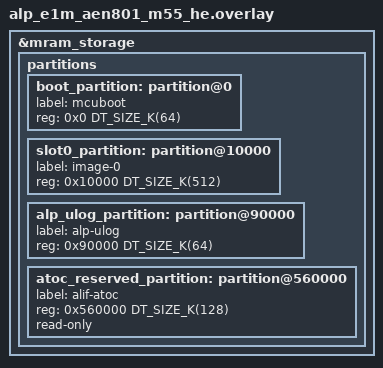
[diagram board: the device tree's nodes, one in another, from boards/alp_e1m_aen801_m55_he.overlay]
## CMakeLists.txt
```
# SPDX-License-Identifier: Apache-2.0
cmake_minimum_required(VERSION 3.20.0)

set(ALP_AEN_UPDATE_LOG_FIREWALL_PROVEN OFF CACHE BOOL
    "Enable only after the AEN MRAM log partition is firewalled and silicon-proven")
set(ALP_AEN_UPDATE_LOG_FIREWALL_PROBE OFF CACHE BOOL
    "Build the HE direct-write MRAM firewall probe instead of the normal HE demo")

if(ALP_AEN_UPDATE_LOG_FIREWALL_PROVEN AND ALP_AEN_UPDATE_LOG_FIREWALL_PROBE)
  message(FATAL_ERROR "Use either ALP_AEN_UPDATE_LOG_FIREWALL_PROVEN or ALP_AEN_UPDATE_LOG_FIREWALL_PROBE, not both")
endif()

# The AEN bench images are loaded to each M55's ITCM by a dual-entry ATOC, while
# the update log itself persists in a dedicated MRAM NVS partition. HE is the
# app/client image; HP is the trusted owner image. Keep this board-only so
# native_sim stays the portable, no-hardware test path.
if(BOARD MATCHES "^alp_e1m_aen801_m55_he")
  set(DTC_OVERLAY_FILE "${CMAKE_CURRENT_SOURCE_DIR}/boards/alp_e1m_aen801_m55_he_ae822fa0e5597ls0_rtss_he.overlay")
  list(APPEND EXTRA_CONF_FILE "${CMAKE_CURRENT_SOURCE_DIR}/boards/alp_e1m_aen801_m55_he_ae822fa0e5597ls0_rtss_he.conf")
  if(ALP_AEN_UPDATE_LOG_FIREWALL_PROVEN)
    message(STATUS "AEN update-log firewall-proof profile enabled")
    list(APPEND EXTRA_CONF_FILE "${CMAKE_CURRENT_SOURCE_DIR}/boards/alp_e1m_aen801_m55_he_firewall_proven.conf")
  endif()
  if(ALP_AEN_UPDATE_LOG_FIREWALL_PROBE)
    message(STATUS "AEN update-log HE direct-write firewall probe enabled")
    list(APPEND EXTRA_CONF_FILE "${CMAKE_CURRENT_SOURCE_DIR}/boards/alp_e1m_aen801_m55_he_firewall_probe.conf")
  endif()
elseif(BOARD MATCHES "^alp_e1m_aen801_m55_hp")
  set(DTC_OVERLAY_FILE "${CMAKE_CURRENT_SOURCE_DIR}/boards/alp_e1m_aen801_m55_hp_ae822fa0e5597ls0_rtss_hp.overlay")
  list(APPEND EXTRA_CONF_FILE "${CMAKE_CURRENT_SOURCE_DIR}/boards/alp_e1m_aen801_m55_hp_ae822fa0e5597ls0_rtss_hp.conf")
endif()

find_package(Zephyr REQUIRED HINTS $ENV{ZEPHYR_BASE})
project(firmware_update_log)

# flash-update-log-dual.sh greps the build's .config for FIREWALL_PROVEN, and the
# HE client only reports HW_ENFORCED with it. Fail the configure step if the
# profile was requested but the Kconfig did not derive it.
if(ALP_AEN_UPDATE_LOG_FIREWALL_PROVEN AND NOT CONFIG_ALP_SDK_UPDATE_LOG_AEN_M55_FIREWALL_PROVEN)
  message(FATAL_ERROR "ALP_AEN_UPDATE_LOG_FIREWALL_PROVEN=ON but the app-immutable profile did not derive CONFIG_ALP_SDK_UPDATE_LOG_AEN_M55_FIREWALL_PROVEN")
endif()
target_sources(app PRIVATE src/main.c)
```

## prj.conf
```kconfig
CONFIG_PRINTK=y
CONFIG_LOG=y
CONFIG_ALP_SDK=y
CONFIG_ALP_SDK_UPDATE_LOG=y

# The update-log engine hashes records on the caller's stack. Keep enough
# main-thread stack for Cortex-M builds with hardware stack protection enabled.
CONFIG_MAIN_STACK_SIZE=4096
```

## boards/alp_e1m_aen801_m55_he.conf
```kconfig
#
# E1M-AEN801 / Alif Ensemble E8: load the HE client to ITCM. HE never opens a
# local persistent update-log store: it is a CLIENT of the HP owner and only
# ever reaches the log by proxying append/verify/count/get over MHU.
#
# alp_ulog_partition is mapped in the shared *_log_mram.dtsi purely so the HP
# owner build (which includes the same dtsi) can carve it out, and so the
# firewall-probe profile can attempt a direct raw flash_write() against it as
# a negative proof. HE's own update-log backend selection must NEVER mount a
# local NVS store on that partition -- it is the HP owner's MRAM region, and
# the update-log engine's lock is per-image, so two NVS instances over one
# region would race with no cross-image serialization. Do NOT set
# CONFIG_ALP_SDK_UPDATE_LOG_PERSIST / CONFIG_NVS here: the software tier's
# ready() probe additionally refuses to engage at all on this CLIENT role
# (src/backends/update_log/sw_tier.c) so this stays fail-closed even if PERSIST
# were mistakenly re-enabled.
#
# This is a client role, not app-immutability by itself. The active assurance
# still comes from alp_update_log_assurance(); it becomes HW_ENFORCED only
# when the real secure owner/firewall-backed backend answers ready().
#
# Keep the AEN bench image fail-closed for the customer policy: if the secure
# owner is not present, the example reports that and exits instead of using a
# local software MRAM/NVS tier as a substitute.
CONFIG_ALP_SOC_ALIF_ENSEMBLE_E8=y
CONFIG_ALP_SDK_UPDATE_LOG_AEN_M55_CLIENT=y
CONFIG_ALP_SDK_UPDATE_LOG_REQUIRE_HW_ENFORCED=y

# Do not set CONFIG_ALP_SDK_UPDATE_LOG_AEN_M55_FIREWALL_PROVEN here. That bit is
# only valid in a provisioned profile after a real HE write-to-log-region probe
# has faulted/rejected on silicon. Without it the HE image remains fail-closed.

# Shared HE<->HP request mailbox lives in global SRAM0. Keep D-cache off until
# the service grows explicit clean/invalidate around that mailbox.
CONFIG_DCACHE=n

# The Alif MRAM flash driver, kept enabled only so the firewall-probe profile
# (EXTRA_CONF_FILE-layered on top of this file) can flash_write()/flash_read()
# alp_ulog_partition directly as its negative proof. HE's own update-log path
# does not use it -- see the comment block above.
CONFIG_FLASH=y
CONFIG_FLASH_MAP=y
CONFIG_FLASH_PAGE_LAYOUT=y
```

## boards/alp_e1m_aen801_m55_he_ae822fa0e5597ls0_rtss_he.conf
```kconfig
#
# E1M-AEN801 / Alif Ensemble E8: load the HE client to ITCM. HE never opens a
# local persistent update-log store: it is a CLIENT of the HP owner and only
# ever reaches the log by proxying append/verify/count/get over MHU.
#
# alp_ulog_partition is mapped in the shared *_log_mram.dtsi purely so the HP
# owner build (which includes the same dtsi) can carve it out, and so the
# firewall-probe profile can attempt a direct raw flash_write() against it as
# a negative proof. HE's own update-log backend selection must NEVER mount a
# local NVS store on that partition -- it is the HP owner's MRAM region, and
# the update-log engine's lock is per-image, so two NVS instances over one
# region would race with no cross-image serialization. Do NOT set
# CONFIG_ALP_SDK_UPDATE_LOG_PERSIST / CONFIG_NVS here: the software tier's
# ready() probe additionally refuses to engage at all on this CLIENT role
# (src/backends/update_log/sw_tier.c) so this stays fail-closed even if PERSIST
# were mistakenly re-enabled.
#
# This is a client role, not app-immutability by itself. The active assurance
# still comes from alp_update_log_assurance(); it becomes HW_ENFORCED only
# when the real secure owner/firewall-backed backend answers ready().
#
# Keep the AEN bench image fail-closed for the customer policy: if the secure
# owner is not present, the example reports that and exits instead of using a
# local software MRAM/NVS tier as a substitute.
CONFIG_ALP_SOC_ALIF_ENSEMBLE_E8=y
CONFIG_ALP_SDK_UPDATE_LOG_AEN_M55_CLIENT=y
CONFIG_ALP_SDK_UPDATE_LOG_REQUIRE_HW_ENFORCED=y

# Do not select CONFIG_ALP_SDK_UPDATE_LOG_AEN_M55_APP_IMMUTABLE_PROFILE here.
# It is only valid in a provisioned profile (boards/*_firewall_proven.conf,
# -DALP_AEN_UPDATE_LOG_FIREWALL_PROVEN=ON) after a real HE write-to-log-region
# probe has faulted/rejected on silicon. Without it the HE image remains
# fail-closed.

# Shared HE<->HP request mailbox lives in global SRAM0. Keep D-cache off until
# the service grows explicit clean/invalidate around that mailbox.
CONFIG_DCACHE=n

# The Alif MRAM flash driver, kept enabled only so the firewall-probe profile
# (EXTRA_CONF_FILE-layered on top of this file) can flash_write()/flash_read()
# alp_ulog_partition directly as its negative proof. HE's own update-log path
# does not use it -- see the comment block above.
CONFIG_FLASH=y
CONFIG_FLASH_MAP=y
CONFIG_FLASH_PAGE_LAYOUT=y
```

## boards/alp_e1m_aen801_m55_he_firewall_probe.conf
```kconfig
#
# E1M-AEN801 / Alif Ensemble E8: HE direct-write firewall probe.
#
# This diagnostic profile intentionally tries to write the first 16 bytes of
# alp_ulog_partition from the HE application core. It is a negative proof: the
# hardware-enforced update-log profile is valid only if this write is rejected,
# blocked from readback, or faults while the MRAM log partition remains
# unchanged.
#
# Do not combine this with CONFIG_ALP_SDK_UPDATE_LOG_AEN_M55_APP_IMMUTABLE_PROFILE.
# The normal demo uses the proven profile after this probe has passed.
#
CONFIG_ALP_SDK_UPDATE_LOG_AEN_M55_FIREWALL_PROBE=y
CONFIG_FAULT_DUMP=2
```

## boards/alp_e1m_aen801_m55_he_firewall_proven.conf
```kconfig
#
# E1M-AEN801 / Alif Ensemble E8: provisioned app-immutable update-log profile.
#
# Select this profile (-DALP_AEN_UPDATE_LOG_FIREWALL_PROVEN=ON) only for a
# board whose provisioning has already locked alp_ulog_partition so the HE
# application core cannot write or erase it, and where that direct-write
# rejection has been proven on silicon with the firewall-probe profile.
#
# This does not program the firewall. It is the one flag that lets the HE
# client report HW_ENFORCED after the HP owner also answers the MHU ready
# request. The Kconfig derives CONFIG_ALP_SDK_UPDATE_LOG_AEN_M55_FIREWALL_PROVEN
# and selects CONFIG_ALP_SDK_UPDATE_LOG_REQUIRE_HW_ENFORCED from it, so do not
# set either of those by hand.
#
CONFIG_ALP_SDK_UPDATE_LOG_AEN_M55_APP_IMMUTABLE_PROFILE=y
```

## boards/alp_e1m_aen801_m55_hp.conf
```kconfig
#
# E1M-AEN801 / Alif Ensemble E8: trusted-owner side of the hardware-enforced
# update-log demo. HP owns the MRAM log partition and services HE requests over
# the RTSS MHU mailbox.
#
CONFIG_ALP_SOC_ALIF_ENSEMBLE_E8=y
CONFIG_ALP_SDK_UPDATE_LOG_AEN_M55_OWNER=y

# HP is the trusted writer, so it opens the local MRAM/NVS log directly. Do not
# require HW_ENFORCED on this side; the HE client is the side that reports the
# security property after the firewall proof and owner-ready checks pass.
CONFIG_ALP_SDK_UPDATE_LOG_REQUIRE_HW_ENFORCED=n

# HP releases HE over the Alif SE service after the dual-image package has
# loaded the HE image but before the owner starts serving requests.
CONFIG_ARM_MHUV2=y
CONFIG_HAS_ALIF_SE_SERVICES=y
CONFIG_ALP_SDK_SECURITY_SE_CRYPTOCELL=n
CONFIG_ALP_SDK_SOC_INFO_ALIF_SE=n
CONFIG_ALP_SDK_POWER_PROFILE_ALIF_SE=n

# Link at the board's zephyr,code-partition (&slot0_partition), so Flow-D
# flashing writes an image whose reset vector is in MRAM slot0 (0x8001xxxx).
CONFIG_USE_DT_CODE_PARTITION=y

# Shared HE<->HP request mailbox lives in global SRAM0. Keep D-cache off until
# the service grows explicit clean/invalidate around that mailbox.
CONFIG_DCACHE=n

# Zephyr NVS over the Alif MRAM flash driver backs alp_ulog_partition.
CONFIG_FLASH=y
CONFIG_FLASH_MAP=y
CONFIG_FLASH_PAGE_LAYOUT=y
CONFIG_NVS=y
CONFIG_ALP_SDK_UPDATE_LOG_PERSIST=y
```

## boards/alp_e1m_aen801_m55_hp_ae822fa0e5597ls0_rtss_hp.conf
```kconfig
#
# E1M-AEN801 / Alif Ensemble E8: trusted-owner side of the hardware-enforced
# update-log demo. HP owns the MRAM log partition and services HE requests over
# the RTSS MHU mailbox.
#
CONFIG_ALP_SOC_ALIF_ENSEMBLE_E8=y
CONFIG_ALP_SDK_UPDATE_LOG_AEN_M55_OWNER=y

# HP is the trusted writer, so it opens the local MRAM/NVS log directly. Do not
# require HW_ENFORCED on this side; the HE client is the side that reports the
# security property after the firewall proof and owner-ready checks pass.
CONFIG_ALP_SDK_UPDATE_LOG_REQUIRE_HW_ENFORCED=n

# HP releases HE over the Alif SE service after the dual-image package has
# loaded the HE image but before the owner starts serving requests.
CONFIG_ARM_MHUV2=y
CONFIG_HAS_ALIF_SE_SERVICES=y
CONFIG_ALP_SDK_SECURITY_SE_CRYPTOCELL=n
CONFIG_ALP_SDK_SOC_INFO_ALIF_SE=n
CONFIG_ALP_SDK_POWER_PROFILE_ALIF_SE=n

# Shared HE<->HP request mailbox lives in global SRAM0. Keep D-cache off until
# the service grows explicit clean/invalidate around that mailbox.
CONFIG_DCACHE=n

# Zephyr NVS over the Alif MRAM flash driver backs alp_ulog_partition.
CONFIG_FLASH=y
CONFIG_FLASH_MAP=y
CONFIG_FLASH_PAGE_LAYOUT=y
CONFIG_NVS=y
CONFIG_ALP_SDK_UPDATE_LOG_PERSIST=y
```

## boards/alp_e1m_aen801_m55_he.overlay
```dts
/*
 * Copyright 2026 Alp Lab AB
 * SPDX-License-Identifier: Apache-2.0
 *
 * E1M-AEN801 / Alif Ensemble E8 MRAM layout for firmware-update-log.
 *
 * The board's production MRAM map uses the top 128 KiB as generic storage.
 * The Alif ATOC package also lives at the top of MRAM in the Flow-D boot path,
 * so this example uses a smaller demo map:
 *
 *   0x000000..0x00ffff  boot placeholder
 *   0x010000..0x08ffff  slot0 image, booted by the SE from MRAM
 *   0x090000..0x09ffff  alp_ulog_partition, Zephyr NVS update-log store
 *   0x560000..0x57ffff  reserved for the Alif ATOC package
 *
 * The update-log partition is deliberately away from the ATOC area. In the
 * hardware-enforced flow, HP owns this partition and HE must be blocked from
 * writing it by the SE/device firewall. Without that firewall policy, MRAM/NVS
 * is only persistence, not app-immutability.
 */

/delete-node/ &boot_partition;
/delete-node/ &slot0_partition;
/delete-node/ &slot1_partition;
/delete-node/ &scratch_partition;
/delete-node/ &storage_partition;

&mram_storage {
	partitions {
		boot_partition: partition@0 {
			label = "mcuboot";
			reg = <0x0 DT_SIZE_K(64)>;
		};

		slot0_partition: partition@10000 {
			label = "image-0";
			reg = <0x10000 DT_SIZE_K(512)>;
		};

		alp_ulog_partition: partition@90000 {
			label = "alp-ulog";
			reg = <0x90000 DT_SIZE_K(64)>;
		};

		atoc_reserved_partition: partition@560000 {
			label = "alif-atoc";
			reg = <0x560000 DT_SIZE_K(128)>;
			read-only;
		};
	};
};
```

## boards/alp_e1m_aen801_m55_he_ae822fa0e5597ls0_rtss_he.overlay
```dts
/*
 * Copyright 2026 Alp Lab AB
 * SPDX-License-Identifier: Apache-2.0
 *
 * E1M-AEN801 / Alif Ensemble E8 HE client overlay for firmware-update-log.
 *
 * HE is loaded to its ITCM global alias (0x58000000) by the dual-entry ATOC.
 * The audit log itself stays in MRAM through the shared alp_ulog_partition.
 */

#include "alp_e1m_aen801_m55_log_mram.dtsi"

/ {
	chosen {
		zephyr,flash = &itcm;
		/delete-property/ zephyr,code-partition;
	};
};
```

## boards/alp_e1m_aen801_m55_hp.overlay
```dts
/*
 * Copyright 2026 Alp Lab AB
 * SPDX-License-Identifier: Apache-2.0
 *
 * HP owner overlay for firmware-update-log.
 *
 * Start from the same MRAM partition map as the HE client so both images agree
 * on alp_ulog_partition, then enable the SE-service nodes HP needs for
 * alp_mproc_boot_core(ALP_CORE_M55_HE, ...).
 */

#include "alp_e1m_aen801_m55_he.overlay"

&seservice0r {
	status = "okay";
};

&seservice0s {
	status = "okay";
};

&se_service {
	status = "okay";
};
```

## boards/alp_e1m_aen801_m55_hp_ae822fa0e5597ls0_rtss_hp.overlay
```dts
/*
 * Copyright 2026 Alp Lab AB
 * SPDX-License-Identifier: Apache-2.0
 *
 * HP owner overlay for firmware-update-log.
 *
 * HP is loaded to its ITCM global alias (0x50000000) and owns the MRAM update
 * log partition. Enable the SE-service nodes HP needs for
 * alp_mproc_boot_core(ALP_CORE_M55_HE, 0x58000000).
 */

#include "alp_e1m_aen801_m55_log_mram.dtsi"

/ {
	chosen {
		zephyr,flash = &itcm;
		/delete-property/ zephyr,code-partition;
	};
};

&seservice0r {
	status = "okay";
};

&seservice0s {
	status = "okay";
};

&se_service {
	status = "okay";
};
```

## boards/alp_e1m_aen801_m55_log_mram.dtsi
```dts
/*
 * Copyright 2026 Alp Lab AB
 * SPDX-License-Identifier: Apache-2.0
 *
 * Shared MRAM layout for the AEN firmware-update-log HE client and HP owner.
 *
 * The demo images are loaded to each core's ITCM by the SE ATOC package. The
 * audit-log body is the part that lives in MRAM, in alp_ulog_partition below.
 *
 *   0x000000..0x00ffff  boot placeholder
 *   0x010000..0x08ffff  unused by this ITCM-loaded demo (each core's real
 *                       slot0 window differs -- see E1M-AEN801.yaml `memory_map:`)
 *   0x090000..0x09ffff  alp_ulog_partition, Zephyr NVS update-log store
 *   0x560000..0x57ffff  reserved for the Alif ATOC package
 *
 * In the hardware-enforced flow, HP owns alp_ulog_partition and HE must be
 * blocked from writing it by the SE/device firewall. Without that firewall
 * policy, MRAM/NVS is persistence only, not application-immutability.
 *
 * alp_ulog_partition ALSO carries the `storage_partition` nodelabel (issue
 * #1101). zephyr/soc-bridge/alif/mpu_regions_e8.c derives its non-MCUboot
 * MRAM_DEVICE window from DT_NODELABEL(storage_partition) -- that is the
 * vendor fork's own contract name (zephyr_alif-ref mpu_regions.c), declared
 * unconditionally at SoC level on every upstream board. A plain rename to
 * `alp_ulog_partition` alone would silently break sw_tier.c's
 * PARTITION_EXISTS(alp_ulog_partition) gate too (src/backends/update_log/
 * sw_tier.c) -- it would just stop finding a *different* name, degrading to
 * the RAM tier with no build error. Two nodelabels on one node is legal DT
 * (see zephyr/boards/st/b_u585i_iot02a/b_u585i_iot02a-common.dtsi's
 * `memc: aps6408l:` for prior art in the pinned toolchain) and resolves both
 * consumers to the same physical node -- do not "simplify" this back to one
 * label.
 *
 * Unlike this board's own default partition map, `storage_partition` here
 * is NOT the last partition in mram_storage -- atoc_reserved_partition sits
 * above it, fixed at 0x560000 by the Alif SE ATOC package. That breaks the
 * vendor model's implicit "storage tiles to top-of-flash" assumption:
 * MRAM_EXEC (0x0..0x90000) + MRAM_DEVICE (0x90000..0xa0000) alone would
 * leave 0xa0000..0x580000 -- ATOC included -- covered by no MPU region, i.e.
 * privileged RW+exec by ARMv8-M default (PRIVDEFENA). mpu_regions_e8.c
 * closes that generically with a conditional fifth "MRAM_RESERVED" RO
 * region that appears only when boot/slot0/storage don't already tile
 * mram_storage (zero-cost on every other board/example, which do tile it);
 * see that file's comment on MRAM_RESERVED_SIZE for the full reasoning.
 */

/delete-node/ &boot_partition;
/delete-node/ &slot0_partition;
/delete-node/ &storage_partition;
/* The board tree's SE-owned band (#1289) is deleted too, because this
 * overlay re-declares it below with a wider extent.  Leaving both in place
 * gives two `fixed-partitions` children with label "atoc", and Zephyr emits
 * `DT_COMPAT_fixed_partitions_LABEL_atoc` once per label:
 *     error: "DT_COMPAT_fixed_partitions_LABEL_atoc" redefined [-Werror]
 */
/delete-node/ &atoc_partition;

&mram_storage {
	partitions {
		boot_partition: partition@0 {
			label = "mcuboot";
			reg = <0x0 DT_SIZE_K(64)>;
		};

		alp_ulog_partition: storage_partition: partition@90000 {
			label = "alp-ulog";
			reg = <0x90000 DT_SIZE_K(64)>;
		};

		/*
		 * SE-owned ATOC band (#1289).  Labelled "atoc" to match the
		 * generated board trees and satisfy
		 * scripts/check_atoc_reservation.py; it read "alif-atoc" before,
		 * which no gate recognised.
		 *
		 * DELIBERATELY over-reserved: the board trees reserve 32 KiB
		 * (0x578000..0x580000) and keep 0x560000..0x578000 as writable
		 * `storage`, but this example replaces the whole partition table
		 * with its own and has no use for that 96 KiB -- so it keeps the
		 * wider band rather than perturbing the MRAM_RESERVED MPU region
		 * described above.  Over-reserving is safe; under-reserving is
		 * what bricks the part.
		 *
		 * NOTE: `read-only;` here is DOCUMENTATION, not enforcement.
		 * Zephyr's flash_area_write() bounds-checks the partition and
		 * never consults this property, so a `read-only;` fixed-partition
		 * child is still writable through a flash_area handle.  What
		 * actually protects this band is that nothing opens it.
		 */
		atoc_reserved_partition: partition@560000 {
			label = "atoc";
			reg = <0x560000 DT_SIZE_K(128)>;
			read-only;
		};
	};
};
```

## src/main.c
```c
/*
 * Copyright 2026 Alp Lab AB
 * SPDX-License-Identifier: Apache-2.0
 *
 * firmware-update-log -- portable, tamper-evident update audit log.
 *
 * This is the ONE API a product uses regardless of SoM. On native_sim and on
 * boards without a secure storage backend, the software tier builds a hash
 * chain and verifies that nobody changed, removed, rolled back, or reordered
 * old records. That is tamper-evident, not app-immutable.
 *
 * On a TF-M build with a real secure owner, the same API can bind to
 * HW_ENFORCED: each entry is a secure-world write-once asset, and the counter
 * is kept in protected storage.
 *
 * On AEN dual-M55 builds the hardware path is split by role: HP is the trusted
 * owner that writes the MRAM log, and HE is the application client that reaches
 * HP through a tiny MHU mailbox service. That split is HARDWARE-enforced by
 * blocking HE from writing the MRAM log partition directly. The block does NOT
 * come from the MRAM slave-side firewall (FC13, 0x80000000+): that range is
 * owned and opened to the application masters by the SERAM firmware and is
 * outside the OEM device config (Alif AUGD0005, "Open Firewall configuration").
 * It comes instead from the HE core's own MASTER-side firewall (FC8), which the
 * OEM ATOC device config CAN program: an allow-all region for every master plus
 * a higher-priority deny carve-out over the log window for HE's master id. With
 * that policy HE boots and runs normally but bus-faults on any direct write to
 * the log partition -- silicon-proven on E8 (the probe below reports RESULT_FAULT
 * at STAGE_WRITE and the MRAM stays unchanged). HE reports HW_ENFORCED once that
 * FC8 policy is provisioned (the app-immutable profile) and the HP owner answers.
 *
 * Flow: open the log, append one update record (as MCUboot/a secure service
 * would after verifying an image), then verify the whole chain and print it.
 */
#include <stdio.h>
#include <string.h>

#include <alp/update_log.h>

#if defined(CONFIG_ALP_SDK_UPDATE_LOG_AEN_M55_FIREWALL_PROBE)
#include <cmsis_core.h>
#include <zephyr/device.h>
#include <zephyr/drivers/flash.h>
#include <zephyr/fatal.h>
#include <zephyr/kernel.h>
#endif

#if defined(CONFIG_ALP_SDK_UPDATE_LOG_AEN_M55_OWNER)
#include <alp/mproc.h>
#endif

#include <zephyr/storage/flash_map.h>

#if defined(CONFIG_ALP_SDK_UPDATE_LOG_AEN_M55_CLIENT)
/* A client never mounts a store of its own: the HP owner owns the MRAM NVS. */
#define UPDATE_LOG_STORAGE_STR "owned by the HP owner (MRAM NVS, reached over MHU)"
#elif defined(CONFIG_ALP_SDK_UPDATE_LOG_PERSIST) && PARTITION_EXISTS(alp_ulog_partition)
/* Whether alp_ulog_partition backs onto the on-die MRAM is a SoC/silicon
 * fact (Alif Ensemble E8, either core, either SKU sharing that die), not a
 * board or SKU one -- CONFIG_SOC_AE822FA0E5597LS0 is select-ed by both
 * *_RTSS_HE and *_RTSS_HP. */
#if defined(CONFIG_SOC_AE822FA0E5597LS0)
#define UPDATE_LOG_STORAGE_STR "MRAM NVS (alp_ulog_partition)"
#else
#define UPDATE_LOG_STORAGE_STR "persistent NVS (alp_ulog_partition)"
#endif
#else
#define UPDATE_LOG_STORAGE_STR "RAM fallback"
#endif

#if defined(CONFIG_ALP_SDK_UPDATE_LOG_AEN_M55_OWNER)
#define HE_LOAD_ADDR 0x58000000U
void update_log_aen_m55_owner_run(void);
#endif

#if !defined(CONFIG_ALP_SDK_UPDATE_LOG_AEN_M55_OWNER)
/* Turn the assurance level into text. This tells the application what guarantee
 * it actually got on this build. */
static const char *assurance_str(alp_update_log_assurance_t a)
{
	return (a == ALP_UPDATE_LOG_HW_ENFORCED) ? "HW_ENFORCED (secure tier)"
	                                         : "SW_TAMPER_EVIDENT (software tier)";
}

/* Turn the verify result into text. Verification checks the whole history, not
 * just the newest entry. */
static const char *verdict_str(alp_update_log_verdict_t v)
{
	switch (v) {
	case ALP_UPDATE_LOG_VERIFY_OK:
		/* The stored history is consistent. */
		return "OK";
	case ALP_UPDATE_LOG_VERIFY_CHAIN_BROKEN:
		/* Someone changed or moved an old entry. */
		return "CHAIN_BROKEN";
	case ALP_UPDATE_LOG_VERIFY_TRUNCATED:
		/* The end of the log is missing. */
		return "TRUNCATED";
	case ALP_UPDATE_LOG_VERIFY_ROLLED_BACK:
		/* The log was replaced with an older copy. */
		return "ROLLED_BACK";
	default:
		return "?";
	}
}
#endif

#if defined(CONFIG_ALP_SDK_UPDATE_LOG_AEN_M55_FIREWALL_PROBE)
#define FIREWALL_PROBE_BEACON       ((volatile uint32_t *)0x02001080U)
#define FIREWALL_PROBE_MAGIC        0x46575052U /* "FWPR" */
#define FIREWALL_PROBE_RESULT_START 1U
#define FIREWALL_PROBE_RESULT_FAULT 2U
#define FIREWALL_PROBE_RESULT_PASS  3U
#define FIREWALL_PROBE_RESULT_FAIL  4U
#define FIREWALL_PROBE_RESULT_ERROR 5U
#define FIREWALL_PROBE_RESULT_CHECK 6U

#define FIREWALL_PROBE_STAGE_IDLE       0U
#define FIREWALL_PROBE_STAGE_PREPARE    1U
#define FIREWALL_PROBE_STAGE_WRITE      2U
#define FIREWALL_PROBE_STAGE_READ_AFTER 3U

static volatile uint32_t g_firewall_probe_stage;
static uint32_t          g_firewall_probe_pattern[4];

static void firewall_probe_stamp(uint32_t result, uint32_t stage, uint32_t detail, uint32_t pc)
{
	FIREWALL_PROBE_BEACON[0] = FIREWALL_PROBE_MAGIC;
	FIREWALL_PROBE_BEACON[1] = result;
	FIREWALL_PROBE_BEACON[2] = stage;
	FIREWALL_PROBE_BEACON[3] = detail;
	FIREWALL_PROBE_BEACON[4] = pc;
	FIREWALL_PROBE_BEACON[5] = SCB->CFSR;
	FIREWALL_PROBE_BEACON[6] = SCB->BFAR;
	FIREWALL_PROBE_BEACON[7] = SCB->HFSR;
#if PARTITION_EXISTS(alp_ulog_partition)
	FIREWALL_PROBE_BEACON[8] = PARTITION_OFFSET(alp_ulog_partition);
#else
	FIREWALL_PROBE_BEACON[8] = 0xFFFFFFFFU;
#endif
	FIREWALL_PROBE_BEACON[9]  = g_firewall_probe_pattern[0];
	FIREWALL_PROBE_BEACON[10] = g_firewall_probe_pattern[1];
	FIREWALL_PROBE_BEACON[11] = g_firewall_probe_pattern[2];
	FIREWALL_PROBE_BEACON[12] = g_firewall_probe_pattern[3];
	__DSB();
	__ISB();
}

void k_sys_fatal_error_handler(unsigned int reason, const struct arch_esf *esf)
{
	uint32_t stage = g_firewall_probe_stage;
	uint32_t pc    = (esf != NULL) ? esf->basic.pc : 0U;
	uint32_t result;

	if (stage == FIREWALL_PROBE_STAGE_WRITE) {
		result = FIREWALL_PROBE_RESULT_FAULT;
	} else if (stage == FIREWALL_PROBE_STAGE_READ_AFTER) {
		result = FIREWALL_PROBE_RESULT_CHECK;
	} else {
		result = FIREWALL_PROBE_RESULT_ERROR;
	}

	firewall_probe_stamp(result, stage, reason, pc);
	for (;;) {
		__WFE();
	}
}

static int run_firewall_probe(void)
{
#if !PARTITION_EXISTS(alp_ulog_partition)
	firewall_probe_stamp(FIREWALL_PROBE_RESULT_ERROR, FIREWALL_PROBE_STAGE_IDLE, 1U, 0U);
	printf("[update-log] firewall probe: alp_ulog_partition is missing\n");
	return 1;
#else
	const struct device *flash = PARTITION_DEVICE(alp_ulog_partition);
	const off_t          off   = PARTITION_OFFSET(alp_ulog_partition);
	uint32_t             after[4];

	firewall_probe_stamp(FIREWALL_PROBE_RESULT_START, FIREWALL_PROBE_STAGE_IDLE, 0U, 0U);
	printf("[update-log] HE direct-write firewall probe: MRAM offset=0x%08lx\n", (long)off);

	if (!device_is_ready(flash)) {
		firewall_probe_stamp(FIREWALL_PROBE_RESULT_ERROR, FIREWALL_PROBE_STAGE_IDLE, 2U, 0U);
		printf("[update-log] firewall probe: MRAM flash device is not ready\n");
		return 1;
	}

	g_firewall_probe_stage      = FIREWALL_PROBE_STAGE_PREPARE;
	uint32_t nonce              = k_cycle_get_32() ^ (uint32_t)off;
	g_firewall_probe_pattern[0] = 0x46575052U; /* "FWPR" */
	g_firewall_probe_pattern[1] = nonce ^ 0x13579BDFU;
	g_firewall_probe_pattern[2] = nonce ^ 0x2468ACE0U;
	g_firewall_probe_pattern[3] = 0x21574C41U; /* "ALW!" */
	g_firewall_probe_stage      = FIREWALL_PROBE_STAGE_IDLE;
	firewall_probe_stamp(FIREWALL_PROBE_RESULT_START, FIREWALL_PROBE_STAGE_IDLE, 0U, 0U);

	g_firewall_probe_stage = FIREWALL_PROBE_STAGE_WRITE;
	int rc = flash_write(flash, off, g_firewall_probe_pattern, sizeof(g_firewall_probe_pattern));
	g_firewall_probe_stage = FIREWALL_PROBE_STAGE_IDLE;

	g_firewall_probe_stage = FIREWALL_PROBE_STAGE_READ_AFTER;
	int read_rc            = flash_read(flash, off, after, sizeof(after));
	g_firewall_probe_stage = FIREWALL_PROBE_STAGE_IDLE;
	if (read_rc != 0) {
		uint32_t detail = (rc == 0) ? 0U : (uint32_t)-rc;
		firewall_probe_stamp(
		    FIREWALL_PROBE_RESULT_CHECK, FIREWALL_PROBE_STAGE_READ_AFTER, detail, 0U);
		printf("[update-log] firewall probe: HE post-read blocked rc=%d; compare by SWD\n",
		       read_rc);
		return 0;
	}

	if (memcmp(after, g_firewall_probe_pattern, sizeof(after)) == 0) {
		firewall_probe_stamp(FIREWALL_PROBE_RESULT_FAIL,
		                     FIREWALL_PROBE_STAGE_WRITE,
		                     (rc == 0) ? 0U : (uint32_t)-rc,
		                     0U);
		printf("[update-log] FAIL: HE direct MRAM write changed alp_ulog_partition\n");
		return 1;
	}

	firewall_probe_stamp(
	    FIREWALL_PROBE_RESULT_PASS, FIREWALL_PROBE_STAGE_WRITE, (rc == 0) ? 0U : (uint32_t)-rc, 0U);
	printf("[update-log] PASS: HE direct MRAM write pattern did not land");
	printf(" (rc=%d)\n", rc);
	return 0;
#endif
}
#endif

int main(void)
{
#if defined(CONFIG_ALP_SDK_UPDATE_LOG_AEN_M55_OWNER)
	printf("[update-log] AEN HP owner: MRAM writer service starting\n");
	printf("[update-log] owner storage: %s\n", UPDATE_LOG_STORAGE_STR);

	/* HP releases HE after the package has loaded the HE image. From then on,
	 * HE can only append by sending an MHU request back to this owner. */
	alp_status_t rc = alp_mproc_boot_core(ALP_CORE_M55_HE, HE_LOAD_ADDR);
	printf("[update-log] released HE rc=%d\n", (int)rc);

	/* This call normally does not return. It opens the local MRAM/NVS log and
	 * serves HE append/verify/count/get requests; if MHU access never becomes
	 * ready, it records that failure in the HP beacon and returns. */
	update_log_aen_m55_owner_run();
	return 0;
#else
#if defined(CONFIG_ALP_SDK_UPDATE_LOG_AEN_M55_FIREWALL_PROBE)
	return run_firewall_probe();
#endif

	/* Open the device's update log. NULL means no backend on this SoM. */
	alp_update_log_t *log = alp_update_log_open();
	if (log == NULL) {
#if defined(CONFIG_ALP_SDK_UPDATE_LOG_REQUIRE_HW_ENFORCED)
		printf("[update-log] HW_ENFORCED required, but no secure owner/firewall-backed backend is "
		       "active\n");
#else
		printf("[update-log] no backend present\n");
#endif
		return 0;
	}

	/* Print the actual guarantee. Do not assume HW_ENFORCED just because the
	 * chip has secure hardware; the backend reports only what this build and
	 * boot path really wired. */
	printf("[update-log] assurance: %s\n", assurance_str(alp_update_log_assurance(log)));
	printf("[update-log] storage: %s\n", UPDATE_LOG_STORAGE_STR);

	/* Record an update result. This example fills the fields by hand so the
	 * flow is easy to read. Production code should prefer
	 * alp_update_log_append_boot(), once the board provides authenticated boot
	 * metadata, so the version/hash/status come from verified boot facts
	 * instead of from normal application data. */
	alp_update_log_entry_t e;
	memset(&e, 0, sizeof(e));

	/* Firmware version we want to record. */
	strncpy(e.fw_version, "1.4.2", ALP_UPDATE_LOG_FWVER_MAX);

	/* Placeholder for the verified image hash. In a product, this should come
	 * from trusted boot metadata, not from the normal application. */
	memset(e.image_hash, 0x5A, sizeof(e.image_hash)); /* SHA-256 of the image */

	/* CONFIRMED means the new firmware booted and was accepted as good.
	 * Timestamp is useful for audits, but the security claim does not depend
	 * on time unless the product has a trusted clock. */
	e.status    = ALP_UPDATE_STATUS_CONFIRMED;
	e.timestamp = 1718000000u; /* best-effort epoch */

	/* Append the record. The log assigns the sequence number, so the app cannot
	 * choose where the entry sits in history. */
	if (alp_update_log_append(log, &e) != ALP_OK) {
		printf("[update-log] append failed\n");
		return 0;
	}

	/* Verify the whole chain. On the software tier this detects a broken
	 * history, but it cannot stop privileged firmware from rebuilding both the
	 * log and its counter. On the hardware tier, old entries live behind the
	 * secure boundary, so normal firmware cannot rewrite them. */
	alp_update_log_verdict_t v;
	uint64_t                 bad = 0;
	if (alp_update_log_verify(log, &v, &bad) == ALP_OK) {
		/* bad would identify the first bad entry. This example prints only
		 * the simple happy path. */
		printf("[update-log] verify: %s\n", verdict_str(v));
	}

	/* Print the audit trail. A product could send the same information to a
	 * cloud service, service tool, or compliance report. */
	uint64_t n = 0;
	if (alp_update_log_count(log, &n) == ALP_OK) {
		printf("[update-log] %llu entr%s:\n", (unsigned long long)n, (n == 1) ? "y" : "ies");
		for (uint64_t i = 0; i < n; i++) {
			alp_update_log_entry_t r;
			if (alp_update_log_get(log, i, &r) == ALP_OK) {
				/* These are the fields an audit usually needs first:
				 * entry number, firmware version, result, and time. */
				printf("  #%llu  v=%s  status=%d  ts=%llu\n",
				       (unsigned long long)r.seq,
				       r.fw_version,
				       (int)r.status,
				       (unsigned long long)r.timestamp);
			}
		}
	}

	/* Close the log handle. */
	alp_update_log_close(log);
	return 0;
#endif
}
```
